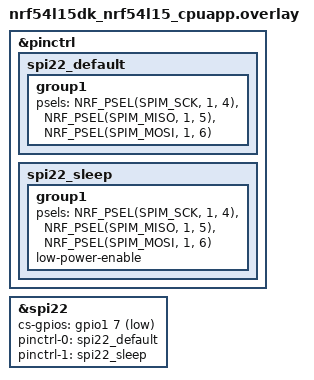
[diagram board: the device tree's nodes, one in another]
/*
 * Copyright (c) 2024 Nordic Semiconductor
 *
 * SPDX-License-Identifier: Apache-2.0
 */

&pinctrl {
	spi22_default: spi22_default {
		group1 {
			psels = <NRF_PSEL(SPIM_SCK,  1, 4)>,
				<NRF_PSEL(SPIM_MISO, 1, 5)>,
				<NRF_PSEL(SPIM_MOSI, 1, 6)>;
		};
	};

	spi22_sleep: spi22_sleep {
		group1 {
			psels = <NRF_PSEL(SPIM_SCK,  1, 4)>,
				<NRF_PSEL(SPIM_MISO, 1, 5)>,
				<NRF_PSEL(SPIM_MOSI, 1, 6)>;
			low-power-enable;
		};
	};
};

edge_connector_spi: &spi22 {
	status = "okay";
	cs-gpios = <&gpio1 7 GPIO_ACTIVE_LOW>;
	pinctrl-0 = <&spi22_default>;
	pinctrl-1 = <&spi22_sleep>;
	pinctrl-names = "default", "sleep";
};

#include "../nrf7002eb2_interposer_p1_gpio_map_1.dtsi"
